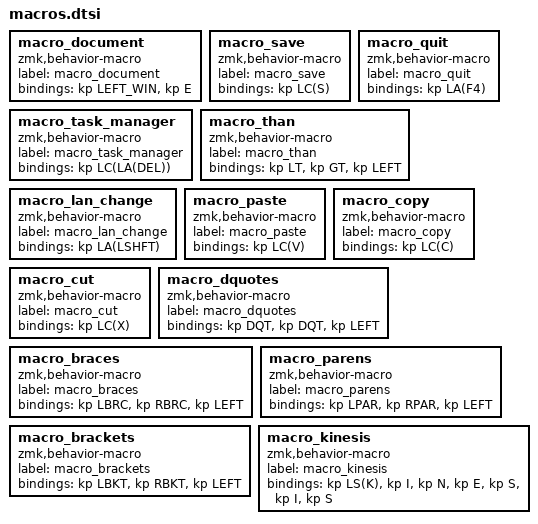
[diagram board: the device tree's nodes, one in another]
macro_document: macro_document{
compatible = "zmk,behavior-macro";
label = "macro_document";
#binding-cells = <0>;
bindings = <&kp LEFT_WIN>, <&kp E>;
};
macro_save: macro_save{
compatible = "zmk,behavior-macro";
label = "macro_save";
#binding-cells = <0>;
bindings = <&kp LC(S)>;
};
macro_quit: macro_quit{
compatible = "zmk,behavior-macro";
label = "macro_quit";
#binding-cells = <0>;
bindings = <&kp LA(F4)>;
};
macro_task_manager: macro_task_manager{
compatible = "zmk,behavior-macro";
label = "macro_task_manager";
#binding-cells = <0>;
bindings = <&kp LC(LA(DEL))>;
};
macro_than: macro_than{
compatible = "zmk,behavior-macro";
label = "macro_than";
#binding-cells = <0>;
bindings = <&kp LT>, <&kp GT>, <&kp LEFT>;
};
macro_lan_change: macro_lan_change{
compatible = "zmk,behavior-macro";
label = "macro_lan_change";
#binding-cells = <0>;
bindings = <&kp LA(LSHFT)>;
};
macro_paste: macro_paste{
compatible = "zmk,behavior-macro";
label = "macro_paste";
#binding-cells = <0>;
bindings = <&kp LC(V)>;
};
macro_copy: macro_copy{
compatible = "zmk,behavior-macro";
label = "macro_copy";
#binding-cells = <0>;
bindings = <&kp LC(C)>;
};
macro_cut: macro_cut{
compatible = "zmk,behavior-macro";
label = "macro_cut";
#binding-cells = <0>;
bindings = <&kp LC(X)>;
};
macro_dquotes: macro_dquotes{
compatible = "zmk,behavior-macro";
label = "macro_dquotes";
#binding-cells = <0>;
bindings = <&kp DQT>, <&kp DQT>, <&kp LEFT>;
};
macro_braces: macro_braces{
compatible = "zmk,behavior-macro";
label = "macro_braces";
#binding-cells = <0>;
bindings = <&kp LBRC>, <&kp RBRC>, <&kp LEFT>;
};
macro_parens: macro_parens{
compatible = "zmk,behavior-macro";
label = "macro_parens";
#binding-cells = <0>;
bindings = <&kp LPAR>, <&kp RPAR>, <&kp LEFT>;
};
macro_brackets: macro_brackets{
compatible = "zmk,behavior-macro";
label = "macro_brackets";
#binding-cells = <0>;
bindings = <&kp LBKT>, <&kp RBKT>, <&kp LEFT>;
};
macro_kinesis: macro_kinesis{
compatible = "zmk,behavior-macro";
label = "macro_kinesis";
#binding-cells = <0>;
bindings = <&kp LS(K)>, <&kp I>, <&kp N>, <&kp E>, <&kp S>, <&kp I>, <&kp S>;
};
